AUTOSAR XML (schema 3.0.2)
package /pk_Simple
  mode declaration group mdg_Simple: initial-mode=md_Init
    mode md_Init
    mode md_Run
  client server interface in_Interface_operation
    operation op_operation
  sender receiver interface modeIfc
    mode declaration group prototype mdgp_Simple: type=mdg_Simple
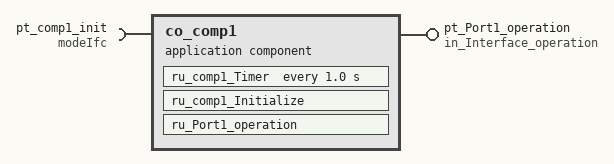
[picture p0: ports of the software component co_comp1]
  application software component type co_comp1
    provide port pt_Port1_operation: provided-interface=in_Interface_operation
    require port pt_comp1_init: required-interface=modeIfc
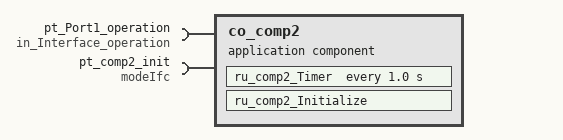
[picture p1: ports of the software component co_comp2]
  application software component type co_comp2
    require port pt_Port1_operation: required-interface=in_Interface_operation
    require port pt_comp2_init: required-interface=modeIfc
  composition type cz_comp1
    provide port pt_Port1_operation: provided-interface=in_Interface_operation
    component cp_comp1: type=co_comp1
    delegate cp_comp1.pt_Port1_operation <-> outer port cz_comp1/pt_Port1_operation
  composition type cz_comp2
    require port pt_Port1_operation: required-interface=in_Interface_operation
    component cp_comp2: type=co_comp2
    delegate cp_comp2.pt_Port1_operation <-> outer port cz_comp2/pt_Port1_operation
  composition type cz_default
    component cp_cz_comp1: type=cz_comp1
    component cp_cz_comp2: type=cz_comp2
    connect cp_cz_comp1.pt_Port1_operation -> cp_cz_comp2.pt_Port1_operation
  internal behavior ib_comp1: component=co_comp1, supports-multiple-instantiation=true
    timing event ev_comp1_Timer: start-on-event=ru_comp1_Timer, period=1.0
    mode switch event ev_comp1_Initialize: start-on-event=ru_comp1_Initialize, activation=ENTRY, mode=pt_comp1_init.mdgp_Simple.md_Init
    operation invoked event ev_Port1_operation: start-on-event=ru_Port1_operation, operation=pt_Port1_operation.op_operation
    exclusive area ea_comp1
    runnable ru_comp1_Timer: can-be-invoked-concurrently=true, can-enter-exclusive-area=ea_comp1, symbol=ib_comp1_ru_comp1Timer
    runnable ru_comp1_Initialize: can-be-invoked-concurrently=true, can-enter-exclusive-area=ea_comp1, symbol=ib_comp1_ru_comp1_Initialize
    runnable ru_Port1_operation: can-be-invoked-concurrently=true, can-enter-exclusive-area=ea_comp1, symbol=ib_comp1_ru_Port1_operation
  internal behavior ib_comp2: component=co_comp2, supports-multiple-instantiation=true
    timing event ev_comp2_Timer: start-on-event=ru_comp2_Timer, period=1.0
    mode switch event ev_comp2_Initialize: start-on-event=ru_comp2_Initialize, activation=ENTRY, mode=pt_comp2_init.mdgp_Simple.md_Init
    exclusive area ea_comp2
    runnable ru_comp2_Timer: can-be-invoked-concurrently=true, can-enter-exclusive-area=ea_comp2, symbol=ib_comp2_ru_comp2Timer
      sync call Port1_operation: operation=pt_Port1_operation.op_operation, timeout=0.5
    runnable ru_comp2_Initialize: can-be-invoked-concurrently=true, can-enter-exclusive-area=ea_comp2, symbol=ib_comp2_ru_comp2_Initialize
  swc implementation im_comp1: code-generator=BridgePoint xtUML MC3020, programming-language=C, behavior=ib_comp1
  swc implementation im_comp2: code-generator=BridgePoint xtUML MC3020, programming-language=C, behavior=ib_comp2
